# ATSAM3X8E register map
Vendor: Atmel; Series: SAM3X; File version: 0
CPU: CM3 r2p0, selectable endian, MPU, no FPU, 4 interrupt priority bits
Registers are 32-bit, read-write, reset 0x0 unless marked. A register's access mark holds for its fields unless they carry their own. Offsets are from the block's base; [hi:lo] are bit positions; {n}, {i} and the like mark numbered series; 'fields as' and 'values as' point back to an identical list.

## SMC — Static Memory Controller
Base 0x400E0000; register names take the prefix SMC_
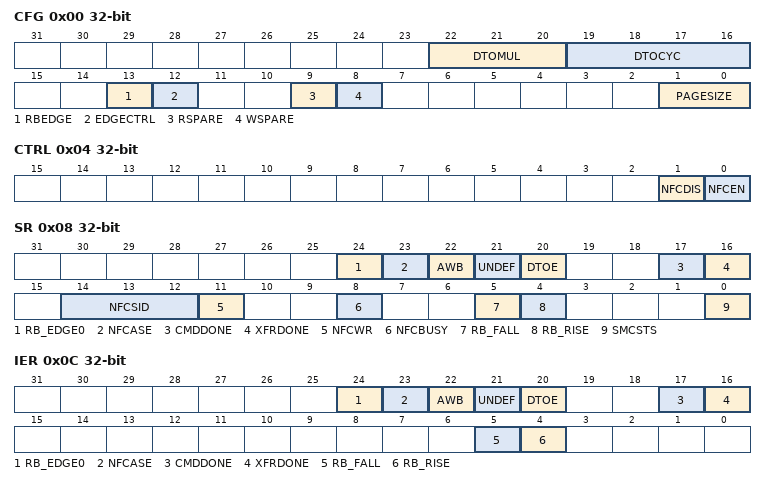
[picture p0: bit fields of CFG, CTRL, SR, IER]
0x00 CFG — SMC NFC Configuration Register
  [22:20] DTOMUL — Data Timeout Multiplier
    0=DTOCYC; 1=X16 (DTOCYC x 16); 2=X128 (DTOCYC x 128); 3=X256 (DTOCYC x 256); 4=X1024 (DTOCYC x 1024); 5=X4096 (DTOCYC x 4096); 6=X65536 (DTOCYC x 65536); 7=X1048576 (DTOCYC x 1048576)
  [19:16] DTOCYC — Data Timeout Cycle Number
  [13] RBEDGE — Ready/Busy Signal Edge Detection
  [12] EDGECTRL — Rising/Falling Edge Detection Control
  [9] RSPARE — Read Spare Area
  [8] WSPARE — Write Spare Area
  [1:0] PAGESIZE — Page Size of the NAND Flash Device
    0=PS512 (Main area 512 Bytes); 1=PS1024 (Main area 1024 Bytes); 2=PS2048 (Main area 2048 Bytes); 3=PS4096 (Main area 4096 Bytes)
0x04 CTRL wo — SMC NFC Control Register
  [1] NFCDIS — NAND Flash Controller Disable
  [0] NFCEN — NAND Flash Controller Enable
0x08 SR ro — SMC NFC Status Register
  [24] RB_EDGE0 — Ready/Busy Line 0 Edge Detected
  [23] NFCASE — NFC Access Size Error
  [22] AWB — Accessing While Busy
  [21] UNDEF — Undefined Area Error
  [20] DTOE — Data Timeout Error
  [17] CMDDONE — Command Done
  [16] XFRDONE — NFC Data Transfer Terminated
  [14:12] NFCSID — NFC Chip Select ID (this field cannot be reset)
  [11] NFCWR — NFC Write/Read Operation (this field cannot be reset)
  [8] NFCBUSY — NFC Busy (this field cannot be reset)
  [5] RB_FALL — Selected Ready Busy Falling Edge Detected
  [4] RB_RISE — Selected Ready Busy Rising Edge Detected
  [0] SMCSTS — NAND Flash Controller status (this field cannot be reset)
0x0C IER wo — SMC NFC Interrupt Enable Register
  [24] RB_EDGE0 — Ready/Busy Line 0 Interrupt Enable
  [23] NFCASE — NFC Access Size Error Interrupt Enable
  [22] AWB — Accessing While Busy Interrupt Enable
  [21] UNDEF — Undefined Area Access Interrupt Enable
  [20] DTOE — Data Timeout Error Interrupt Enable
  [17] CMDDONE — Command Done Interrupt Enable
  [16] XFRDONE — Transfer Done Interrupt Enable
  [5] RB_FALL — Ready Busy Falling Edge Detection Interrupt Enable
  [4] RB_RISE — Ready Busy Rising Edge Detection Interrupt Enable
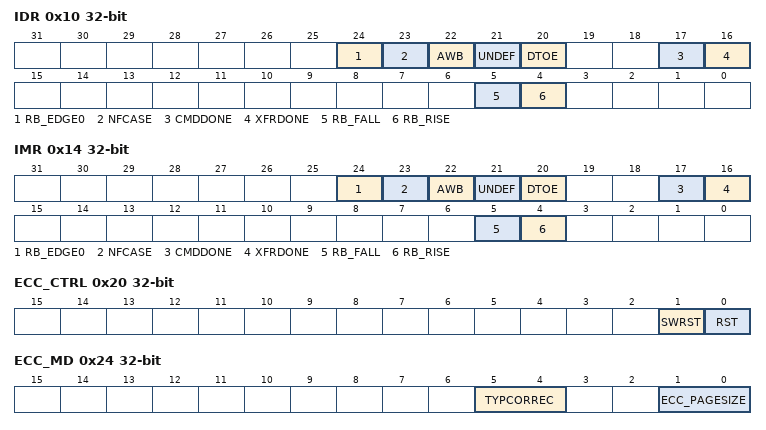
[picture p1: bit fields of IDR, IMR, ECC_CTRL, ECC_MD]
0x10 IDR wo — SMC NFC Interrupt Disable Register
  [24] RB_EDGE0 — Ready/Busy Line 0 Interrupt Disable
  [23] NFCASE — NFC Access Size Error Interrupt Disable
  [22] AWB — Accessing While Busy Interrupt Disable
  [21] UNDEF — Undefined Area Access Interrupt Disable
  [20] DTOE — Data Timeout Error Interrupt Disable
  [17] CMDDONE — Command Done Interrupt Disable
  [16] XFRDONE — Transfer Done Interrupt Disable
  [5] RB_FALL — Ready Busy Falling Edge Detection Interrupt Disable
  [4] RB_RISE — Ready Busy Rising Edge Detection Interrupt Disable
0x14 IMR ro — SMC NFC Interrupt Mask Register
  [24] RB_EDGE0 — Ready/Busy Line 0 Interrupt Mask
  [23] NFCASE — NFC Access Size Error Interrupt Mask
  [22] AWB — Accessing While Busy Interrupt Mask
  [21] UNDEF — Undefined Area Access Interrupt Mask5
  [20] DTOE — Data Timeout Error Interrupt Mask
  [17] CMDDONE — Command Done Interrupt Mask
  [16] XFRDONE — Transfer Done Interrupt Mask
  [5] RB_FALL — Ready Busy Falling Edge Detection Interrupt Mask
  [4] RB_RISE — Ready Busy Rising Edge Detection Interrupt Mask
0x18 ADDR — SMC NFC Address Cycle Zero Register
  [7:0] ADDR_CYCLE0 — NAND Flash Array Address cycle 0
0x1C BANK — SMC Bank Address Register
  [2:0] BANK — Bank Identifier
0x20 ECC_CTRL wo — SMC ECC Control Register
  [1] SWRST — Software Reset
  [0] RST — Reset ECC
0x24 ECC_MD — SMC ECC Mode Register
  [5:4] TYPCORREC — Type of Correction
    0=CPAGE (1 bit correction for a page of 512/1024/2048/4096 Bytes (for 8 or 16-bit NAND Flash)); 1=C256B (1 bit correction for 256 Bytes of data for a page of 512/2048/4096 bytes (for 8-bit NAND Flash only)); 2=C512B (1 bit correction for 512 Bytes of data for a page of 512/2048/4096 bytes (for 8-bit NAND Flash only))
  [1:0] ECC_PAGESIZE
    0=PS512 (Main area 512 Words); 1=PS1024 (Main area 1024 Words); 2=PS2048 (Main area 2048 Words); 3=PS4096 (Main area 4096 Words)
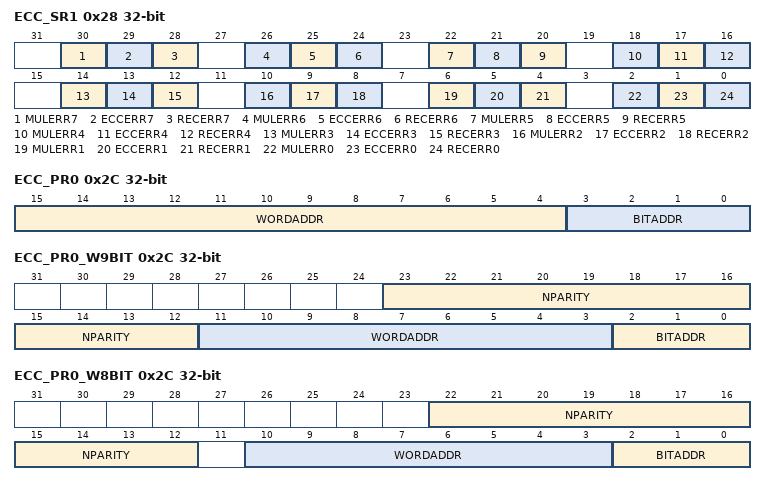
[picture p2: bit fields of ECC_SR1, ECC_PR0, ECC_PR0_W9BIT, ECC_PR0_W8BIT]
0x28 ECC_SR1 ro — SMC ECC Status 1 Register
  [30] MULERR7 — Multiple Error in the page between the 1792nd and the 2047th bytes or between the 3584th and the 4095th bytes
  [29] ECCERR7 — ECC Error in the page between the 1792nd and the 2047th bytes or between the 3584th and the 4095th bytes
  [28] RECERR7 — Recoverable Error in the page between the 1792nd and the 2047th bytes or between the 3584th and the 4095th bytes
  [26] MULERR6 — Multiple Error in the page between the 1536th and the 1791st bytes or between the 3072nd and the 3583rd bytes
  [25] ECCERR6 — ECC Error in the page between the 1536th and the 1791st bytes or between the 3072nd and the 3583rd bytes
  [24] RECERR6 — Recoverable Error in the page between the 1536th and the 1791st bytes or between the 3072nd and the 3583rd bytes
  [22] MULERR5 — Multiple Error in the page between the 1280th and the 1535th bytes or between the 2560th and the 3071st bytes
  [21] ECCERR5 — ECC Error in the page between the 1280th and the 1535th bytes or between the 2560th and the 3071st bytes
  [20] RECERR5 — Recoverable Error in the page between the 1280th and the 1535th bytes or between the 2560th and the 3071st bytes
  [18] MULERR4 — Multiple Error in the page between the 1024th and the 1279th bytes or between the 2048th and the 2559th bytes
  [17] ECCERR4 — ECC Error in the page between the 1024th and the 1279th bytes or between the 2048th and the 2559th bytes
  [16] RECERR4 — Recoverable Error in the page between the 1024th and the 1279th bytes or between the 2048th and the 2559th bytes
  [14] MULERR3 — Multiple Error in the page between the 768th and the 1023rd bytes or between the 1536th and the 2047th bytes
  [13] ECCERR3 — ECC Error in the page between the 768th and the 1023rd bytes or between the 1536th and the 2047th bytes
  [12] RECERR3 — Recoverable Error in the page between the 768th and the 1023rd bytes or between the 1536th and the 2047th bytes
  [10] MULERR2 — Multiple Error in the page between the 512nd and the 767th bytes or between the 1024th and the 1535th bytes
  [9] ECCERR2 — ECC Error in the page between the 512nd and the 767th bytes or between the 1024th and the 1535th bytes
  [8] RECERR2 — Recoverable Error in the page between the 512nd and the 767th bytes or between the 1024th and the 1535th bytes
  [6] MULERR1 — Multiple Error in the page between the 256th and the 511th bytes or between the 512nd and the 1023rd bytes
  [5] ECCERR1 — ECC Error in the page between the 256th and the 511th bytes or between the 512nd and the 1023rd bytes
  [4] RECERR1 — Recoverable Error in the page between the 256th and the 511th bytes or the 512nd and the 1023rd bytes
  [2] MULERR0 — Multiple Error
  [1] ECCERR0 — ECC Error
  [0] RECERR0 — Recoverable Error
0x2C ECC_PR0 ro — SMC ECC Parity 0 Register
  [15:4] WORDADDR — Word Address
  [3:0] BITADDR — Bit Address
0x2C ECC_PR0_W9BIT ro (W9BIT view) — SMC ECC Parity 0 Register
  [23:12] NPARITY — Parity N
  [11:3] WORDADDR — Corrupted Word Address in the Page between (i x 512) and ((i + 1) x 512) - 1) Bytes
  [2:0] BITADDR — Corrupted Bit Address in the Page between (i x 512) and ((i + 1) x 512) - 1) Bytes
0x2C ECC_PR0_W8BIT ro (W8BIT view) — SMC ECC Parity 0 Register
  [22:12] NPARITY — Parity N
  [10:3] WORDADDR — Corrupted Word Address in the Page between (i x 256) and ((i + 1) x 512) - 1) Bytes
  [2:0] BITADDR — Corrupted Bit Address in the Page between (i x 256) and ((i + 1) x 512) - 1) Bytes
0x30 ECC_PR1 ro — SMC ECC parity 1 Register
  [15:0] NPARITY — Parity N
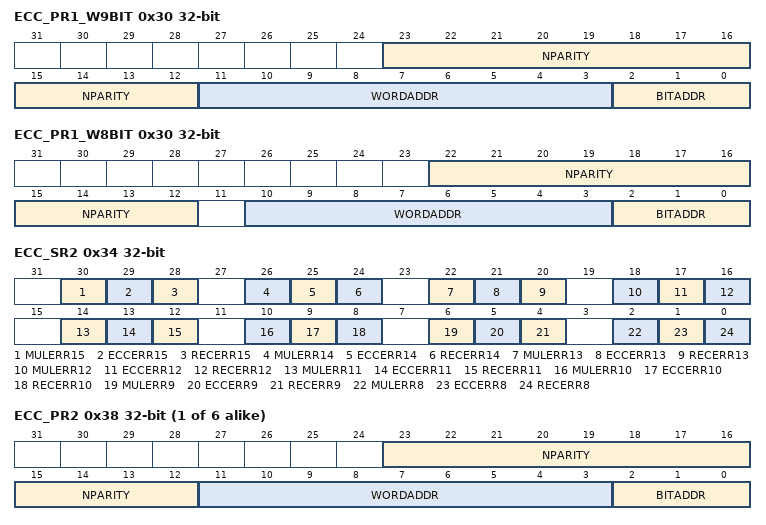
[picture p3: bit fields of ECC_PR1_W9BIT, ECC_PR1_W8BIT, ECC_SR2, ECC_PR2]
0x30 ECC_PR1_W9BIT ro (W9BIT view) — SMC ECC parity 1 Register
  fields as ECC_PR0_W9BIT
0x30 ECC_PR1_W8BIT ro (W8BIT view) — SMC ECC parity 1 Register
  fields as ECC_PR0_W8BIT
0x34 ECC_SR2 ro — SMC ECC status 2 Register
  [30] MULERR15 — Multiple Error in the page between the 3840th and the 4095th bytes
  [29] ECCERR15 — ECC Error in the page between the 3840th and the 4095th bytes
  [28] RECERR15 — Recoverable Error in the page between the 3840th and the 4095th bytes
  [26] MULERR14 — Multiple Error in the page between the 3584th and the 3839th bytes
  [25] ECCERR14 — ECC Error in the page between the 3584th and the 3839th bytes
  [24] RECERR14 — Recoverable Error in the page between the 3584th and the 3839th bytes
  [22] MULERR13 — Multiple Error in the page between the 3328th and the 3583rd bytes
  [21] ECCERR13 — ECC Error in the page between the 3328th and the 3583rd bytes
  [20] RECERR13 — Recoverable Error in the page between the 3328th and the 3583rd bytes
  [18] MULERR12 — Multiple Error in the page between the 3072nd and the 3327th bytes
  [17] ECCERR12 — ECC Error in the page between the 3072nd and the 3327th bytes
  [16] RECERR12 — Recoverable Error in the page between the 3072nd and the 3327th bytes
  [14] MULERR11 — Multiple Error in the page between the 2816th and the 3071st bytes
  [13] ECCERR11 — ECC Error in the page between the 2816th and the 3071st bytes
  [12] RECERR11 — Recoverable Error in the page between the 2816th and the 3071st bytes
  [10] MULERR10 — Multiple Error in the page between the 2560th and the 2815th bytes
  [9] ECCERR10 — ECC Error in the page between the 2560th and the 2815th bytes
  [8] RECERR10 — Recoverable Error in the page between the 2560th and the 2815th bytes
  [6] MULERR9 — Multiple Error in the page between the 2304th and the 2559th bytes
  [5] ECCERR9 — ECC Error in the page between the 2304th and the 2559th bytes
  [4] RECERR9 — Recoverable Error in the page between the 2304th and the 2559th bytes
  [2] MULERR8 — Multiple Error in the page between the 2048th and the 2303rd bytes
  [1] ECCERR8 — ECC Error in the page between the 2048th and the 2303rd bytes
  [0] RECERR8 — Recoverable Error in the page between the 2048th and the 2303rd bytes
{0x30+4i} ECC_PR{i} ro (i=2..7) — SMC ECC parity {i} Register
  fields as ECC_PR0_W9BIT
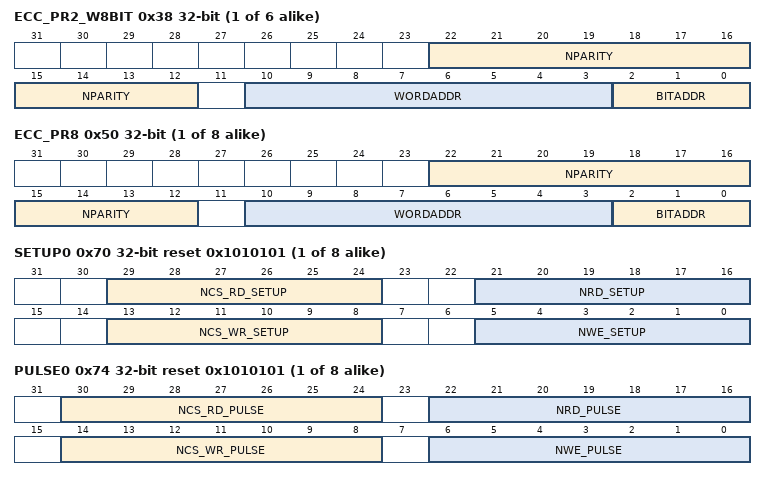
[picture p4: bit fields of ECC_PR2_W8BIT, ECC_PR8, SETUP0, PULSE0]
{0x30+4i} ECC_PR{i}_W8BIT ro (W8BIT view) (i=2..7) — SMC ECC parity {i} Register
  fields as ECC_PR0_W8BIT
{0x30+4i} ECC_PR{i} ro (i=8..15) — SMC ECC parity {i} Register
  fields as ECC_PR0_W8BIT
{0x70+0x14*i} SETUP{i} reset 0x1010101 (i=0..7) — SMC Setup Register (CS_number = {i})
  [29:24] NCS_RD_SETUP — NCS Setup Length in Read Access
  [21:16] NRD_SETUP — NRD Setup Length
  [13:8] NCS_WR_SETUP — NCS Setup Length in Write Access
  [5:0] NWE_SETUP — NWE Setup Length
{0x74+0x14*i} PULSE{i} reset 0x1010101 (i=0..7) — SMC Pulse Register (CS_number = {i})
  [30:24] NCS_RD_PULSE — NCS Pulse Length in READ Access
  [22:16] NRD_PULSE — NRD Pulse Length
  [14:8] NCS_WR_PULSE — NCS Pulse Length in WRITE Access
  [6:0] NWE_PULSE — NWE Pulse Length
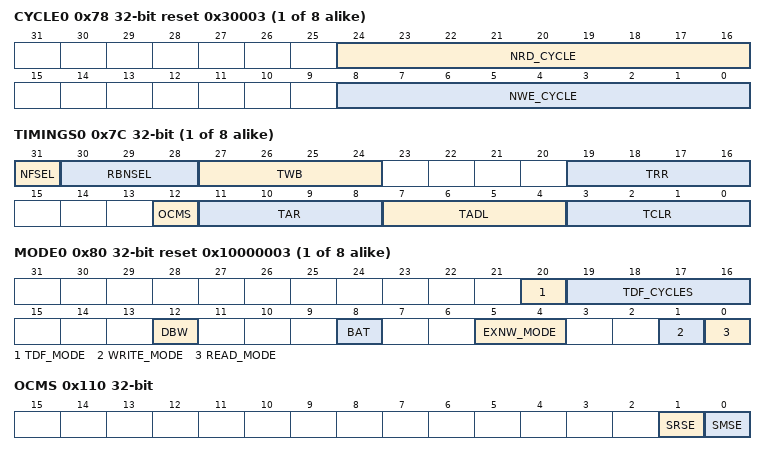
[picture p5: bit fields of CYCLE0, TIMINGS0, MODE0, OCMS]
{0x78+0x14*i} CYCLE{i} reset 0x30003 (i=0..7) — SMC Cycle Register (CS_number = {i})
  [24:16] NRD_CYCLE — Total Read Cycle Length
  [8:0] NWE_CYCLE — Total Write Cycle Length
{0x7C+0x14*i} TIMINGS{i} (i=0..7) — SMC Timings Register (CS_number = {i})
  [31] NFSEL — NAND Flash Selection
  [30:28] RBNSEL — Ready/Busy Line Selection
  [27:24] TWB — WEN High to REN to Busy
  [19:16] TRR — Ready to REN Low Delay
  [12] OCMS — Off Chip Memory Scrambling Enable
  [11:8] TAR — ALE to REN Low Delay
  [7:4] TADL — ALE to Data Start
  [3:0] TCLR — CLE to REN Low Delay
{0x80+0x14*i} MODE{i} reset 0x10000003 (i=0..7) — SMC Mode Register (CS_number = {i})
  [20] TDF_MODE — TDF Optimization
  [19:16] TDF_CYCLES — Data Float Time
  [12] DBW — Data Bus Width
    0=BIT_8 (8-bit bus); 1=BIT_16 (16-bit bus)
  [8] BAT — Byte Access Type
  [5:4] EXNW_MODE — NWAIT Mode
    0=DISABLED; 2=FROZEN (Frozen Mode); 3=READY (Ready Mode)
  [1] WRITE_MODE — Selection of the Control Signal for Write Operation
    0=NCS_CTRL (The Write operation is controller by the NCS signal.); 1=NWE_CTRL (The Write operation is controlled by the NWE signal.)
  [0] READ_MODE — Selection of the Control Signal for Read Operation
    0=NCS_CTRL (The Read operation is controlled by the NCS signal.); 1=NRD_CTRL (The Read operation is controlled by the NRD signal.)
0x110 OCMS — SMC OCMS Register
  [1] SRSE — SRAM Scrambling Enable
  [0] SMSE — Static Memory Controller Scrambling Enable
0x114 KEY1 wo — SMC OCMS KEY1 Register
  [31:0] KEY1 — Off Chip Memory Scrambling (OCMS) Key Part 1
0x118 KEY2 wo — SMC OCMS KEY2 Register
  [31:0] KEY2 — Off Chip Memory Scrambling (OCMS) Key Part 2
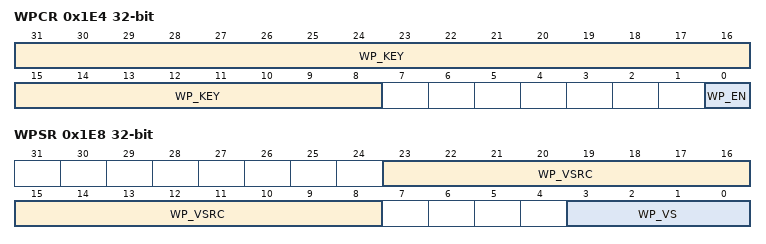
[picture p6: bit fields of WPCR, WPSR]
0x1E4 WPCR wo — Write Protection Control Register
  [31:8] WP_KEY — Write Protection KEY Password
    0x534D43=PASSWD (Writing any other value in this field aborts the write operation of the WP_EN bit. Always reads as 0.)
  [0] WP_EN — Write Protection Enable
0x1E8 WPSR ro — Write Protection Status Register
  [23:8] WP_VSRC — Write Protection Violation Source
  [3:0] WP_VS — Write Protection Violation Status

## Notices in the file
SAM Software Package License
Copyright (c) 2015, Atmel Corporation
All rights reserved.
Redistribution and use in source and binary forms, with or without
modification, are permitted provided that the following condition is met:
- Redistributions of source code must retain the above copyright notice,
this list of conditions and the disclaimer below.
Atmel's name may not be used to endorse or promote products derived from
this software without specific prior written permission.
DISCLAIMER:  THIS SOFTWARE IS PROVIDED BY ATMEL "AS IS" AND ANY EXPRESS OR
IMPLIED WARRANTIES, INCLUDING, BUT NOT LIMITED TO, THE IMPLIED WARRANTIES OF
MERCHANTABILITY, FITNESS FOR A PARTICULAR PURPOSE AND NON-INFRINGEMENT ARE
DISCLAIMED. IN NO EVENT SHALL ATMEL BE LIABLE FOR ANY DIRECT, INDIRECT,
INCIDENTAL, SPECIAL, EXEMPLARY, OR CONSEQUENTIAL DAMAGES (INCLUDING, BUT NOT
LIMITED TO, PROCUREMENT OF SUBSTITUTE GOODS OR SERVICES; LOSS OF USE, DATA,
OR PROFITS; OR BUSINESS INTERRUPTION) HOWEVER CAUSED AND ON ANY THEORY OF
LIABILITY, WHETHER IN CONTRACT, STRICT LIABILITY, OR TORT (INCLUDING
NEGLIGENCE OR OTHERWISE) ARISING IN ANY WAY OUT OF THE USE OF THIS SOFTWARE,
EVEN IF ADVISED OF THE POSSIBILITY OF SUCH DAMAGE.
